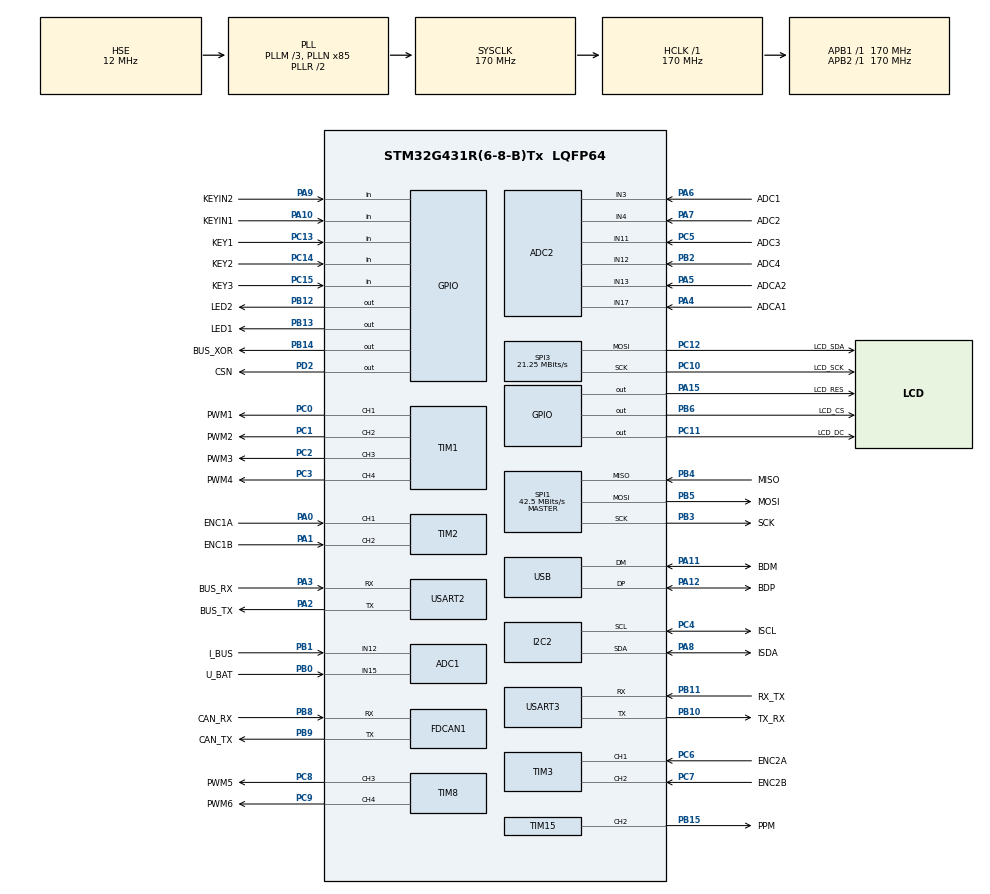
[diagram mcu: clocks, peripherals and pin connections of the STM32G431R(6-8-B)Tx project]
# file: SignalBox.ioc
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ADC1.Channel-0\#ChannelRegularConversion=ADC_CHANNEL_TEMPSENSOR_ADC1
ADC1.NbrOfConversionFlag=1
ADC1.OffsetNumber-0\#ChannelRegularConversion=ADC_OFFSET_NONE
ADC1.Rank-0\#ChannelRegularConversion=1
ADC1.SamplingTime-0\#ChannelRegularConversion=ADC_SAMPLETIME_2CYCLES_5
ADC1.master=1
ADC2.Channel-1\#ChannelRegularConversion=ADC_CHANNEL_3
ADC2.NbrOfConversionFlag=1
ADC2.OffsetNumber-1\#ChannelRegularConversion=ADC_OFFSET_NONE
ADC2.Rank-1\#ChannelRegularConversion=1
ADC2.SamplingTime-1\#ChannelRegularConversion=ADC_SAMPLETIME_2CYCLES_5
FDCAN1.CalculateBaudRateNominal=2125000
FDCAN1.CalculateTimeBitNominal=470
FDCAN1.CalculateTimeQuantumNominal=94.11764705882354
I2C2.Timing=0x30A0A7FB
Mcu.Family=STM32G4
Mcu.Name=STM32G431R(6-8-B)Tx
Mcu.Package=LQFP64
NVIC.PriorityGroup=NVIC_PRIORITYGROUP_4
NVIC.USB_LP_IRQn=true\:0\:0\:false\:false\:true\:false\:true\:true
PA0.GPIO_Label=ENC1A
PA0.Signal=S_TIM2_CH1
PA1.GPIO_Label=ENC1B
PA1.Signal=S_TIM2_CH2
PA10.GPIO_Label=KEYIN1
PA10.Signal=GPIO_Input
PA11.GPIO_Label=BDM
PA11.Mode=Device
PA11.Signal=USB_DM
PA12.GPIO_Label=BDP
PA12.Mode=Device
PA12.Signal=USB_DP
PA13.GPIO_Label=SWDIO
PA13.Mode=Serial_Wire
PA13.Signal=SYS_JTMS-SWDIO
PA14.GPIO_Label=SWCLK
PA14.Mode=Serial_Wire
PA14.Signal=SYS_JTCK-SWCLK
PA15.GPIO_Label=LCD_RES
PA15.Signal=GPIO_Output
PA2.GPIO_Label=BUS_TX
PA2.Mode=Asynchronous
PA2.Signal=USART2_TX
PA3.GPIO_Label=BUS_RX
PA3.Mode=Asynchronous
PA3.Signal=USART2_RX
PA4.GPIO_Label=ADCA1
PA4.Mode=IN17-Single-Ended
PA4.Signal=ADC2_IN17
PA5.GPIO_Label=ADCA2
PA5.Mode=IN13-Single-Ended
PA5.Signal=ADC2_IN13
PA6.GPIO_Label=ADC1
PA6.Mode=IN3-Single-Ended
PA6.Signal=ADC2_IN3
PA7.GPIO_Label=ADC2
PA7.Mode=IN4-Single-Ended
PA7.Signal=ADC2_IN4
PA8.GPIO_Label=ISDA
PA8.Mode=I2C
PA8.Signal=I2C2_SDA
PA9.GPIO_Label=KEYIN2
PA9.Signal=GPIO_Input
PB0.GPIO_Label=U_BAT
PB0.Mode=IN15-Single-Ended
PB0.Signal=ADC1_IN15
PB1.GPIO_Label=I_BUS
PB1.Mode=IN12-Single-Ended
PB1.Signal=ADC1_IN12
PB10.GPIO_Label=TX_RX
PB10.Mode=Asynchronous
PB10.Signal=USART3_TX
PB11.GPIO_Label=RX_TX
PB11.Mode=Asynchronous
PB11.Signal=USART3_RX
PB12.GPIO_Label=LED2
PB12.Signal=GPIO_Output
PB13.GPIO_Label=LED1
PB13.Signal=GPIO_Output
PB14.GPIO_Label=BUS_XOR
PB14.Signal=GPIO_Output
PB15.GPIO_Label=PPM
PB15.Signal=S_TIM15_CH2
PB2.GPIO_Label=ADC4
PB2.Mode=IN12-Single-Ended
PB2.Signal=ADC2_IN12
PB3.GPIO_Label=SCK
PB3.Mode=Full_Duplex_Master
PB3.Signal=SPI1_SCK
PB4.GPIO_Label=MISO
PB4.Mode=Full_Duplex_Master
PB4.Signal=SPI1_MISO
PB5.GPIO_Label=MOSI
PB5.Mode=Full_Duplex_Master
PB5.Signal=SPI1_MOSI
PB6.GPIO_Label=LCD_CS
PB6.Signal=GPIO_Output
PB8-BOOT0.GPIO_Label=CAN_RX
PB8-BOOT0.Mode=FDCAN_Activate
PB8-BOOT0.Signal=FDCAN1_RX
PB9.GPIO_Label=CAN_TX
PB9.Mode=FDCAN_Activate
PB9.Signal=FDCAN1_TX
PC0.GPIO_Label=PWM1
PC0.Signal=S_TIM1_CH1
PC1.GPIO_Label=PWM2
PC1.Signal=S_TIM1_CH2
PC10.GPIO_Label=LCD_SCK
PC10.Mode=TX_Only_Simplex_Unidirect_Master
PC10.Signal=SPI3_SCK
PC11.GPIO_Label=LCD_DC
PC11.Signal=GPIO_Output
PC12.GPIO_Label=LCD_SDA
PC12.Mode=TX_Only_Simplex_Unidirect_Master
PC12.Signal=SPI3_MOSI
PC13.GPIO_Label=KEY1
PC13.Signal=GPIO_Input
PC14-OSC32_IN.GPIO_Label=KEY2
PC14-OSC32_IN.Signal=GPIO_Input
PC15-OSC32_OUT.GPIO_Label=KEY3
PC15-OSC32_OUT.Signal=GPIO_Input
PC2.GPIO_Label=PWM3
PC2.Signal=S_TIM1_CH3
PC3.GPIO_Label=PWM4
PC3.Signal=S_TIM1_CH4
PC4.GPIO_Label=ISCL
PC4.Mode=I2C
PC4.Signal=I2C2_SCL
PC5.GPIO_Label=ADC3
PC5.Mode=IN11-Single-Ended
PC5.Signal=ADC2_IN11
PC6.GPIO_Label=ENC2A
PC6.Signal=S_TIM3_CH1
PC7.GPIO_Label=ENC2B
PC7.Signal=S_TIM3_CH2
PC8.GPIO_Label=PWM5
PC8.Signal=S_TIM8_CH3
PC9.GPIO_Label=PWM6
PC9.Signal=S_TIM8_CH4
PD2.GPIO_Label=CSN
PD2.Signal=GPIO_Output
PF0-OSC_IN.GPIO_Label=O_IN
PF0-OSC_IN.Mode=HSE-External-Oscillator
PF0-OSC_IN.Signal=RCC_OSC_IN
PF1-OSC_OUT.GPIO_Label=O_OUT
PF1-OSC_OUT.Mode=HSE-External-Oscillator
PF1-OSC_OUT.Signal=RCC_OSC_OUT
ProjectManager.HeapSize=0x200
ProjectManager.StackSize=0x400
ProjectManager.TargetToolchain=STM32CubeIDE
RCC.ADC12Freq_Value=170000000
RCC.AHBFreq_Value=170000000
RCC.APB1Freq_Value=170000000
RCC.APB1TimFreq_Value=170000000
RCC.APB2Freq_Value=170000000
RCC.APB2TimFreq_Value=170000000
RCC.CK48CLockSelection=RCC_USBCLKSOURCE_HSI48
RCC.CortexFreq_Value=170000000
RCC.EXTERNAL_CLOCK_VALUE=12288000
RCC.HCLKFreq_Value=170000000
RCC.HSE_VALUE=12000000
RCC.HSI48_VALUE=48000000
RCC.HSI_VALUE=16000000
RCC.LSE_VALUE=32768
RCC.PLLM=RCC_PLLM_DIV3
RCC.PLLN=85
RCC.PLLSourceVirtual=RCC_PLLSOURCE_HSE
RCC.SYSCLKFreq_VALUE=170000000
RCC.SYSCLKSource=RCC_SYSCLKSOURCE_PLLCLK
RCC.USBFreq_Value=48000000
RCC.VCOOutputFreq_Value=340000000
SH.S_TIM15_CH2.0=TIM15_CH2,PWM Generation2 CH2
SH.S_TIM1_CH1.0=TIM1_CH1,PWM Generation1 CH1
SH.S_TIM1_CH2.0=TIM1_CH2,PWM Generation2 CH2
SH.S_TIM1_CH3.0=TIM1_CH3,PWM Generation3 CH3
SH.S_TIM1_CH4.0=TIM1_CH4,PWM Generation4 CH4
SH.S_TIM2_CH1.0=TIM2_CH1,Encoder_Interface
SH.S_TIM2_CH2.0=TIM2_CH2,Encoder_Interface
SH.S_TIM3_CH1.0=TIM3_CH1,Encoder_Interface
SH.S_TIM3_CH2.0=TIM3_CH2,Encoder_Interface
SH.S_TIM8_CH3.0=TIM8_CH3,PWM Generation3 CH3
SH.S_TIM8_CH4.0=TIM8_CH4,PWM Generation4 CH4
SPI1.BaudRatePrescaler=SPI_BAUDRATEPRESCALER_4
SPI1.CalculateBaudRate=42.5 MBits/s
SPI1.Direction=SPI_DIRECTION_2LINES
SPI1.Mode=SPI_MODE_MASTER
SPI1.VirtualType=VM_MASTER
SPI3.BaudRatePrescaler=SPI_BAUDRATEPRESCALER_8
SPI3.CalculateBaudRate=21.25 MBits/s
SPI3.Direction=SPI_DIRECTION_2LINES
SPI3.Mode=SPI_MODE_MASTER
SPI3.VirtualType=VM_MASTER
TIM1.Channel-PWM\ Generation1\ CH1=TIM_CHANNEL_1
TIM1.Channel-PWM\ Generation2\ CH2=TIM_CHANNEL_2
TIM1.Channel-PWM\ Generation3\ CH3=TIM_CHANNEL_3
TIM1.Channel-PWM\ Generation4\ CH4=TIM_CHANNEL_4
TIM15.Channel-PWM\ Generation2\ CH2=TIM_CHANNEL_2
TIM17.Channel=TIM_CHANNEL_1
TIM8.Channel-PWM\ Generation3\ CH3=TIM_CHANNEL_3
TIM8.Channel-PWM\ Generation4\ CH4=TIM_CHANNEL_4
USART2.VirtualMode-Asynchronous=VM_ASYNC
USART3.VirtualMode-Asynchronous=VM_ASYNC
USB_DEVICE.CLASS_NAME_FS=CDC
USB_DEVICE.VirtualMode=Cdc
USB_DEVICE.VirtualModeFS=Cdc_FS
VP_ADC1_TempSens_Input.Mode=IN-TempSens
VP_SYS_VS_DBSignals.Mode=DisableDeadBatterySignals
VP_TIM17_VS_ClockSourceINT.Mode=Enable_Timer
VP_TIM17_VS_no_output1.Mode=Output Compare1 No Output
VP_USB_DEVICE_VS_USB_DEVICE_CDC_FS.Mode=CDC_FS
board=custom

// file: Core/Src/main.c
/* USER CODE BEGIN Header */
/**
  ******************************************************************************
  * @file           : main.c
  * @brief          : Main program body
  ******************************************************************************
  * @attention
  *
  * Copyright (c) 2024 STMicroelectronics.
  * All rights reserved.
  *
  * This software is licensed under terms that can be found in the LICENSE file
  * in the root directory of this software component.
  * If no LICENSE file comes with this software, it is provided AS-IS.
  *
  ******************************************************************************
  */
/* USER CODE END Header */
#include "main.h"
#include "usb_device.h"

ADC_HandleTypeDef hadc1;
ADC_HandleTypeDef hadc2;

FDCAN_HandleTypeDef hfdcan1;

I2C_HandleTypeDef hi2c2;

SPI_HandleTypeDef hspi1;
SPI_HandleTypeDef hspi3;

TIM_HandleTypeDef htim1;
TIM_HandleTypeDef htim2;
TIM_HandleTypeDef htim3;
TIM_HandleTypeDef htim8;
TIM_HandleTypeDef htim15;
TIM_HandleTypeDef htim17;

UART_HandleTypeDef huart2;
UART_HandleTypeDef huart3;

void SystemClock_Config(void);
static void MX_GPIO_Init(void);
static void MX_FDCAN1_Init(void);
static void MX_SPI1_Init(void);
static void MX_SPI3_Init(void);
static void MX_USART3_UART_Init(void);
static void MX_ADC1_Init(void);
static void MX_ADC2_Init(void);
static void MX_I2C2_Init(void);
static void MX_TIM1_Init(void);
static void MX_TIM2_Init(void);
static void MX_TIM3_Init(void);
static void MX_TIM8_Init(void);
static void MX_TIM15_Init(void);
static void MX_TIM17_Init(void);
static void MX_USART2_UART_Init(void);

int main(void)
{

  /* MCU Configuration--------------------------------------------------------*/

  /* Reset of all peripherals, Initializes the Flash interface and the Systick. */
  HAL_Init();

  /* Configure the system clock */
  SystemClock_Config();

  /* Initialize all configured peripherals */
  MX_GPIO_Init();
  MX_FDCAN1_Init();
  MX_SPI1_Init();
  MX_SPI3_Init();
  MX_USART3_UART_Init();
  MX_USB_Device_Init();
  MX_ADC1_Init();
  MX_ADC2_Init();
  MX_I2C2_Init();
  MX_TIM1_Init();
  MX_TIM2_Init();
  MX_TIM3_Init();
  MX_TIM8_Init();
  MX_TIM15_Init();
  MX_TIM17_Init();
  MX_USART2_UART_Init();

  /* Infinite loop */
  while (1)
  {

    /* USER CODE BEGIN 3 */
	HAL_GPIO_WritePin(LED1_GPIO_Port, LED1_Pin, !HAL_GPIO_ReadPin(KEY1_GPIO_Port, KEY1_Pin));
	HAL_GPIO_WritePin(LED2_GPIO_Port, LED2_Pin, !HAL_GPIO_ReadPin(KEY2_GPIO_Port, KEY2_Pin));
  }
  /* USER CODE END 3 */
}

void SystemClock_Config(void)
{
  RCC_OscInitTypeDef RCC_OscInitStruct = {0};
  RCC_ClkInitTypeDef RCC_ClkInitStruct = {0};

  /** Configure the main internal regulator output voltage
  */
  HAL_PWREx_ControlVoltageScaling(PWR_REGULATOR_VOLTAGE_SCALE1_BOOST);

  /** Initializes the RCC Oscillators according to the specified parameters
  * in the RCC_OscInitTypeDef structure.
  */
  RCC_OscInitStruct.OscillatorType = RCC_OSCILLATORTYPE_HSI48|RCC_OSCILLATORTYPE_HSE;
  RCC_OscInitStruct.HSEState = RCC_HSE_ON;
  RCC_OscInitStruct.HSI48State = RCC_HSI48_ON;
  RCC_OscInitStruct.PLL.PLLState = RCC_PLL_ON;
  RCC_OscInitStruct.PLL.PLLSource = RCC_PLLSOURCE_HSE;
  RCC_OscInitStruct.PLL.PLLM = RCC_PLLM_DIV3;
  RCC_OscInitStruct.PLL.PLLN = 85;
  RCC_OscInitStruct.PLL.PLLP = RCC_PLLP_DIV2;
  RCC_OscInitStruct.PLL.PLLQ = RCC_PLLQ_DIV2;
  RCC_OscInitStruct.PLL.PLLR = RCC_PLLR_DIV2;
  if (HAL_RCC_OscConfig(&RCC_OscInitStruct) != HAL_OK)
  {
    Error_Handler();
  }

  /** Initializes the CPU, AHB and APB buses clocks
  */
  RCC_ClkInitStruct.ClockType = RCC_CLOCKTYPE_HCLK|RCC_CLOCKTYPE_SYSCLK
                              |RCC_CLOCKTYPE_PCLK1|RCC_CLOCKTYPE_PCLK2;
  RCC_ClkInitStruct.SYSCLKSource = RCC_SYSCLKSOURCE_PLLCLK;
  RCC_ClkInitStruct.AHBCLKDivider = RCC_SYSCLK_DIV1;
  RCC_ClkInitStruct.APB1CLKDivider = RCC_HCLK_DIV1;
  RCC_ClkInitStruct.APB2CLKDivider = RCC_HCLK_DIV1;

  if (HAL_RCC_ClockConfig(&RCC_ClkInitStruct, FLASH_LATENCY_4) != HAL_OK)
  {
    Error_Handler();
  }
}

static void MX_ADC1_Init(void)
{

  ADC_MultiModeTypeDef multimode = {0};
  ADC_ChannelConfTypeDef sConfig = {0};

  /** Common config
  */
  hadc1.Instance = ADC1;
  hadc1.Init.ClockPrescaler = ADC_CLOCK_SYNC_PCLK_DIV4;
  hadc1.Init.Resolution = ADC_RESOLUTION_12B;
  hadc1.Init.DataAlign = ADC_DATAALIGN_RIGHT;
  hadc1.Init.GainCompensation = 0;
  hadc1.Init.ScanConvMode = ADC_SCAN_DISABLE;
  hadc1.Init.EOCSelection = ADC_EOC_SINGLE_CONV;
  hadc1.Init.LowPowerAutoWait = DISABLE;
  hadc1.Init.ContinuousConvMode = DISABLE;
  hadc1.Init.NbrOfConversion = 1;
  hadc1.Init.DiscontinuousConvMode = DISABLE;
  hadc1.Init.ExternalTrigConv = ADC_SOFTWARE_START;
  hadc1.Init.ExternalTrigConvEdge = ADC_EXTERNALTRIGCONVEDGE_NONE;
  hadc1.Init.DMAContinuousRequests = DISABLE;
  hadc1.Init.Overrun = ADC_OVR_DATA_PRESERVED;
  hadc1.Init.OversamplingMode = DISABLE;
  if (HAL_ADC_Init(&hadc1) != HAL_OK)
  {
    Error_Handler();
  }

  /** Configure the ADC multi-mode
  */
  multimode.Mode = ADC_MODE_INDEPENDENT;
  if (HAL_ADCEx_MultiModeConfigChannel(&hadc1, &multimode) != HAL_OK)
  {
    Error_Handler();
  }

  /** Configure Regular Channel
  */
  sConfig.Channel = ADC_CHANNEL_TEMPSENSOR_ADC1;
  sConfig.Rank = ADC_REGULAR_RANK_1;
  sConfig.SamplingTime = ADC_SAMPLETIME_2CYCLES_5;
  sConfig.SingleDiff = ADC_SINGLE_ENDED;
  sConfig.OffsetNumber = ADC_OFFSET_NONE;
  sConfig.Offset = 0;
  if (HAL_ADC_ConfigChannel(&hadc1, &sConfig) != HAL_OK)
  {
    Error_Handler();
  }

}

static void MX_ADC2_Init(void)
{

  ADC_ChannelConfTypeDef sConfig = {0};

  /** Common config
  */
  hadc2.Instance = ADC2;
  hadc2.Init.ClockPrescaler = ADC_CLOCK_SYNC_PCLK_DIV4;
  hadc2.Init.Resolution = ADC_RESOLUTION_12B;
  hadc2.Init.DataAlign = ADC_DATAALIGN_RIGHT;
  hadc2.Init.GainCompensation = 0;
  hadc2.Init.ScanConvMode = ADC_SCAN_DISABLE;
  hadc2.Init.EOCSelection = ADC_EOC_SINGLE_CONV;
  hadc2.Init.LowPowerAutoWait = DISABLE;
  hadc2.Init.ContinuousConvMode = DISABLE;
  hadc2.Init.NbrOfConversion = 1;
  hadc2.Init.DiscontinuousConvMode = DISABLE;
  hadc2.Init.ExternalTrigConv = ADC_SOFTWARE_START;
  hadc2.Init.ExternalTrigConvEdge = ADC_EXTERNALTRIGCONVEDGE_NONE;
  hadc2.Init.DMAContinuousRequests = DISABLE;
  hadc2.Init.Overrun = ADC_OVR_DATA_PRESERVED;
  hadc2.Init.OversamplingMode = DISABLE;
  if (HAL_ADC_Init(&hadc2) != HAL_OK)
  {
    Error_Handler();
  }

  /** Configure Regular Channel
  */
  sConfig.Channel = ADC_CHANNEL_3;
  sConfig.Rank = ADC_REGULAR_RANK_1;
  sConfig.SamplingTime = ADC_SAMPLETIME_2CYCLES_5;
  sConfig.SingleDiff = ADC_SINGLE_ENDED;
  sConfig.OffsetNumber = ADC_OFFSET_NONE;
  sConfig.Offset = 0;
  if (HAL_ADC_ConfigChannel(&hadc2, &sConfig) != HAL_OK)
  {
    Error_Handler();
  }

}

static void MX_FDCAN1_Init(void)
{

  hfdcan1.Instance = FDCAN1;
  hfdcan1.Init.ClockDivider = FDCAN_CLOCK_DIV1;
  hfdcan1.Init.FrameFormat = FDCAN_FRAME_CLASSIC;
  hfdcan1.Init.Mode = FDCAN_MODE_NORMAL;
  hfdcan1.Init.AutoRetransmission = DISABLE;
  hfdcan1.Init.TransmitPause = DISABLE;
  hfdcan1.Init.ProtocolException = DISABLE;
  hfdcan1.Init.NominalPrescaler = 16;
  hfdcan1.Init.NominalSyncJumpWidth = 1;
  hfdcan1.Init.NominalTimeSeg1 = 2;
  hfdcan1.Init.NominalTimeSeg2 = 2;
  hfdcan1.Init.DataPrescaler = 1;
  hfdcan1.Init.DataSyncJumpWidth = 1;
  hfdcan1.Init.DataTimeSeg1 = 1;
  hfdcan1.Init.DataTimeSeg2 = 1;
  hfdcan1.Init.StdFiltersNbr = 0;
  hfdcan1.Init.ExtFiltersNbr = 0;
  hfdcan1.Init.TxFifoQueueMode = FDCAN_TX_FIFO_OPERATION;
  if (HAL_FDCAN_Init(&hfdcan1) != HAL_OK)
  {
    Error_Handler();
  }

}

static void MX_I2C2_Init(void)
{

  hi2c2.Instance = I2C2;
  hi2c2.Init.Timing = 0x30A0A7FB;
  hi2c2.Init.OwnAddress1 = 0;
  hi2c2.Init.AddressingMode = I2C_ADDRESSINGMODE_7BIT;
  hi2c2.Init.DualAddressMode = I2C_DUALADDRESS_DISABLE;
  hi2c2.Init.OwnAddress2 = 0;
  hi2c2.Init.OwnAddress2Masks = I2C_OA2_NOMASK;
  hi2c2.Init.GeneralCallMode = I2C_GENERALCALL_DISABLE;
  hi2c2.Init.NoStretchMode = I2C_NOSTRETCH_DISABLE;
  if (HAL_I2C_Init(&hi2c2) != HAL_OK)
  {
    Error_Handler();
  }

  /** Configure Analogue filter
  */
  if (HAL_I2CEx_ConfigAnalogFilter(&hi2c2, I2C_ANALOGFILTER_ENABLE) != HAL_OK)
  {
    Error_Handler();
  }

  /** Configure Digital filter
  */
  if (HAL_I2CEx_ConfigDigitalFilter(&hi2c2, 0) != HAL_OK)
  {
    Error_Handler();
  }

}

static void MX_SPI1_Init(void)
{

  /* SPI1 parameter configuration*/
  hspi1.Instance = SPI1;
  hspi1.Init.Mode = SPI_MODE_MASTER;
  hspi1.Init.Direction = SPI_DIRECTION_2LINES;
  hspi1.Init.DataSize = SPI_DATASIZE_4BIT;
  hspi1.Init.CLKPolarity = SPI_POLARITY_LOW;
  hspi1.Init.CLKPhase = SPI_PHASE_1EDGE;
  hspi1.Init.NSS = SPI_NSS_SOFT;
  hspi1.Init.BaudRatePrescaler = SPI_BAUDRATEPRESCALER_4;
  hspi1.Init.FirstBit = SPI_FIRSTBIT_MSB;
  hspi1.Init.TIMode = SPI_TIMODE_DISABLE;
  hspi1.Init.CRCCalculation = SPI_CRCCALCULATION_DISABLE;
  hspi1.Init.CRCPolynomial = 7;
  hspi1.Init.CRCLength = SPI_CRC_LENGTH_DATASIZE;
  hspi1.Init.NSSPMode = SPI_NSS_PULSE_ENABLE;
  if (HAL_SPI_Init(&hspi1) != HAL_OK)
  {
    Error_Handler();
  }

}

static void MX_SPI3_Init(void)
{

  /* SPI3 parameter configuration*/
  hspi3.Instance = SPI3;
  hspi3.Init.Mode = SPI_MODE_MASTER;
  hspi3.Init.Direction = SPI_DIRECTION_2LINES;
  hspi3.Init.DataSize = SPI_DATASIZE_4BIT;
  hspi3.Init.CLKPolarity = SPI_POLARITY_LOW;
  hspi3.Init.CLKPhase = SPI_PHASE_1EDGE;
  hspi3.Init.NSS = SPI_NSS_SOFT;
  hspi3.Init.BaudRatePrescaler = SPI_BAUDRATEPRESCALER_8;
  hspi3.Init.FirstBit = SPI_FIRSTBIT_MSB;
  hspi3.Init.TIMode = SPI_TIMODE_DISABLE;
  hspi3.Init.CRCCalculation = SPI_CRCCALCULATION_DISABLE;
  hspi3.Init.CRCPolynomial = 7;
  hspi3.Init.CRCLength = SPI_CRC_LENGTH_DATASIZE;
  hspi3.Init.NSSPMode = SPI_NSS_PULSE_ENABLE;
  if (HAL_SPI_Init(&hspi3) != HAL_OK)
  {
    Error_Handler();
  }

}

static void MX_TIM1_Init(void)
{

  TIM_MasterConfigTypeDef sMasterConfig = {0};
  TIM_OC_InitTypeDef sConfigOC = {0};
  TIM_BreakDeadTimeConfigTypeDef sBreakDeadTimeConfig = {0};

  htim1.Instance = TIM1;
  htim1.Init.Prescaler = 0;
  htim1.Init.CounterMode = TIM_COUNTERMODE_UP;
  htim1.Init.Period = 65535;
  htim1.Init.ClockDivision = TIM_CLOCKDIVISION_DIV1;
  htim1.Init.RepetitionCounter = 0;
  htim1.Init.AutoReloadPreload = TIM_AUTORELOAD_PRELOAD_DISABLE;
  if (HAL_TIM_PWM_Init(&htim1) != HAL_OK)
  {
    Error_Handler();
  }
  sMasterConfig.MasterOutputTrigger = TIM_TRGO_RESET;
  sMasterConfig.MasterOutputTrigger2 = TIM_TRGO2_RESET;
  sMasterConfig.MasterSlaveMode = TIM_MASTERSLAVEMODE_DISABLE;
  if (HAL_TIMEx_MasterConfigSynchronization(&htim1, &sMasterConfig) != HAL_OK)
  {
    Error_Handler();
  }
  sConfigOC.OCMode = TIM_OCMODE_PWM1;
  sConfigOC.Pulse = 0;
  sConfigOC.OCPolarity = TIM_OCPOLARITY_HIGH;
  sConfigOC.OCNPolarity = TIM_OCNPOLARITY_HIGH;
  sConfigOC.OCFastMode = TIM_OCFAST_DISABLE;
  sConfigOC.OCIdleState = TIM_OCIDLESTATE_RESET;
  sConfigOC.OCNIdleState = TIM_OCNIDLESTATE_RESET;
  if (HAL_TIM_PWM_ConfigChannel(&htim1, &sConfigOC, TIM_CHANNEL_1) != HAL_OK)
  {
    Error_Handler();
  }
  if (HAL_TIM_PWM_ConfigChannel(&htim1, &sConfigOC, TIM_CHANNEL_2) != HAL_OK)
  {
    Error_Handler();
  }
  if (HAL_TIM_PWM_ConfigChannel(&htim1, &sConfigOC, TIM_CHANNEL_3) != HAL_OK)
  {
    Error_Handler();
  }
  if (HAL_TIM_PWM_ConfigChannel(&htim1, &sConfigOC, TIM_CHANNEL_4) != HAL_OK)
  {
    Error_Handler();
  }
  sBreakDeadTimeConfig.OffStateRunMode = TIM_OSSR_DISABLE;
  sBreakDeadTimeConfig.OffStateIDLEMode = TIM_OSSI_DISABLE;
  sBreakDeadTimeConfig.LockLevel = TIM_LOCKLEVEL_OFF;
  sBreakDeadTimeConfig.DeadTime = 0;
  sBreakDeadTimeConfig.BreakState = TIM_BREAK_DISABLE;
  sBreakDeadTimeConfig.BreakPolarity = TIM_BREAKPOLARITY_HIGH;
  sBreakDeadTimeConfig.BreakFilter = 0;
  sBreakDeadTimeConfig.BreakAFMode = TIM_BREAK_AFMODE_INPUT;
  sBreakDeadTimeConfig.Break2State = TIM_BREAK2_DISABLE;
  sBreakDeadTimeConfig.Break2Polarity = TIM_BREAK2POLARITY_HIGH;
  sBreakDeadTimeConfig.Break2Filter = 0;
  sBreakDeadTimeConfig.Break2AFMode = TIM_BREAK_AFMODE_INPUT;
  sBreakDeadTimeConfig.AutomaticOutput = TIM_AUTOMATICOUTPUT_DISABLE;
  if (HAL_TIMEx_ConfigBreakDeadTime(&htim1, &sBreakDeadTimeConfig) != HAL_OK)
  {
    Error_Handler();
  }
  HAL_TIM_MspPostInit(&htim1);

}

static void MX_TIM2_Init(void)
{

  TIM_Encoder_InitTypeDef sConfig = {0};
  TIM_MasterConfigTypeDef sMasterConfig = {0};

  htim2.Instance = TIM2;
  htim2.Init.Prescaler = 0;
  htim2.Init.CounterMode = TIM_COUNTERMODE_UP;
  htim2.Init.Period = 4294967295;
  htim2.Init.ClockDivision = TIM_CLOCKDIVISION_DIV1;
  htim2.Init.AutoReloadPreload = TIM_AUTORELOAD_PRELOAD_DISABLE;
  sConfig.EncoderMode = TIM_ENCODERMODE_TI1;
  sConfig.IC1Polarity = TIM_ICPOLARITY_RISING;
  sConfig.IC1Selection = TIM_ICSELECTION_DIRECTTI;
  sConfig.IC1Prescaler = TIM_ICPSC_DIV1;
  sConfig.IC1Filter = 0;
  sConfig.IC2Polarity = TIM_ICPOLARITY_RISING;
  sConfig.IC2Selection = TIM_ICSELECTION_DIRECTTI;
  sConfig.IC2Prescaler = TIM_ICPSC_DIV1;
  sConfig.IC2Filter = 0;
  if (HAL_TIM_Encoder_Init(&htim2, &sConfig) != HAL_OK)
  {
    Error_Handler();
  }
  sMasterConfig.MasterOutputTrigger = TIM_TRGO_RESET;
  sMasterConfig.MasterSlaveMode = TIM_MASTERSLAVEMODE_DISABLE;
  if (HAL_TIMEx_MasterConfigSynchronization(&htim2, &sMasterConfig) != HAL_OK)
  {
    Error_Handler();
  }

}

static void MX_TIM3_Init(void)
{

  TIM_Encoder_InitTypeDef sConfig = {0};
  TIM_MasterConfigTypeDef sMasterConfig = {0};

  htim3.Instance = TIM3;
  htim3.Init.Prescaler = 0;
  htim3.Init.CounterMode = TIM_COUNTERMODE_UP;
  htim3.Init.Period = 65535;
  htim3.Init.ClockDivision = TIM_CLOCKDIVISION_DIV1;
  htim3.Init.AutoReloadPreload = TIM_AUTORELOAD_PRELOAD_DISABLE;
  sConfig.EncoderMode = TIM_ENCODERMODE_TI1;
  sConfig.IC1Polarity = TIM_ICPOLARITY_RISING;
  sConfig.IC1Selection = TIM_ICSELECTION_DIRECTTI;
  sConfig.IC1Prescaler = TIM_ICPSC_DIV1;
  sConfig.IC1Filter = 0;
  sConfig.IC2Polarity = TIM_ICPOLARITY_RISING;
  sConfig.IC2Selection = TIM_ICSELECTION_DIRECTTI;
  sConfig.IC2Prescaler = TIM_ICPSC_DIV1;
  sConfig.IC2Filter = 0;
  if (HAL_TIM_Encoder_Init(&htim3, &sConfig) != HAL_OK)
  {
    Error_Handler();
  }
  sMasterConfig.MasterOutputTrigger = TIM_TRGO_RESET;
  sMasterConfig.MasterSlaveMode = TIM_MASTERSLAVEMODE_DISABLE;
  if (HAL_TIMEx_MasterConfigSynchronization(&htim3, &sMasterConfig) != HAL_OK)
  {
    Error_Handler();
  }

}

static void MX_TIM8_Init(void)
{

  TIM_MasterConfigTypeDef sMasterConfig = {0};
  TIM_OC_InitTypeDef sConfigOC = {0};
  TIM_BreakDeadTimeConfigTypeDef sBreakDeadTimeConfig = {0};

  htim8.Instance = TIM8;
  htim8.Init.Prescaler = 0;
  htim8.Init.CounterMode = TIM_COUNTERMODE_UP;
  htim8.Init.Period = 65535;
  htim8.Init.ClockDivision = TIM_CLOCKDIVISION_DIV1;
  htim8.Init.RepetitionCounter = 0;
  htim8.Init.AutoReloadPreload = TIM_AUTORELOAD_PRELOAD_DISABLE;
  if (HAL_TIM_PWM_Init(&htim8) != HAL_OK)
  {
    Error_Handler();
  }
  sMasterConfig.MasterOutputTrigger = TIM_TRGO_RESET;
  sMasterConfig.MasterOutputTrigger2 = TIM_TRGO2_RESET;
  sMasterConfig.MasterSlaveMode = TIM_MASTERSLAVEMODE_DISABLE;
  if (HAL_TIMEx_MasterConfigSynchronization(&htim8, &sMasterConfig) != HAL_OK)
  {
    Error_Handler();
  }
  sConfigOC.OCMode = TIM_OCMODE_PWM1;
  sConfigOC.Pulse = 0;
  sConfigOC.OCPolarity = TIM_OCPOLARITY_HIGH;
  sConfigOC.OCNPolarity = TIM_OCNPOLARITY_HIGH;
  sConfigOC.OCFastMode = TIM_OCFAST_DISABLE;
  sConfigOC.OCIdleState = TIM_OCIDLESTATE_RESET;
  sConfigOC.OCNIdleState = TIM_OCNIDLESTATE_RESET;
  if (HAL_TIM_PWM_ConfigChannel(&htim8, &sConfigOC, TIM_CHANNEL_3) != HAL_OK)
  {
    Error_Handler();
  }
  if (HAL_TIM_PWM_ConfigChannel(&htim8, &sConfigOC, TIM_CHANNEL_4) != HAL_OK)
  {
    Error_Handler();
  }
  sBreakDeadTimeConfig.OffStateRunMode = TIM_OSSR_DISABLE;
  sBreakDeadTimeConfig.OffStateIDLEMode = TIM_OSSI_DISABLE;
  sBreakDeadTimeConfig.LockLevel = TIM_LOCKLEVEL_OFF;
  sBreakDeadTimeConfig.DeadTime = 0;
  sBreakDeadTimeConfig.BreakState = TIM_BREAK_DISABLE;
  sBreakDeadTimeConfig.BreakPolarity = TIM_BREAKPOLARITY_HIGH;
  sBreakDeadTimeConfig.BreakFilter = 0;
  sBreakDeadTimeConfig.BreakAFMode = TIM_BREAK_AFMODE_INPUT;
  sBreakDeadTimeConfig.Break2State = TIM_BREAK2_DISABLE;
  sBreakDeadTimeConfig.Break2Polarity = TIM_BREAK2POLARITY_HIGH;
  sBreakDeadTimeConfig.Break2Filter = 0;
  sBreakDeadTimeConfig.Break2AFMode = TIM_BREAK_AFMODE_INPUT;
  sBreakDeadTimeConfig.AutomaticOutput = TIM_AUTOMATICOUTPUT_DISABLE;
  if (HAL_TIMEx_ConfigBreakDeadTime(&htim8, &sBreakDeadTimeConfig) != HAL_OK)
  {
    Error_Handler();
  }
  HAL_TIM_MspPostInit(&htim8);

}

static void MX_TIM15_Init(void)
{

  TIM_MasterConfigTypeDef sMasterConfig = {0};
  TIM_OC_InitTypeDef sConfigOC = {0};
  TIM_BreakDeadTimeConfigTypeDef sBreakDeadTimeConfig = {0};

  htim15.Instance = TIM15;
  htim15.Init.Prescaler = 0;
  htim15.Init.CounterMode = TIM_COUNTERMODE_UP;
  htim15.Init.Period = 65535;
  htim15.Init.ClockDivision = TIM_CLOCKDIVISION_DIV1;
  htim15.Init.RepetitionCounter = 0;
  htim15.Init.AutoReloadPreload = TIM_AUTORELOAD_PRELOAD_DISABLE;
  if (HAL_TIM_PWM_Init(&htim15) != HAL_OK)
  {
    Error_Handler();
  }
  sMasterConfig.MasterOutputTrigger = TIM_TRGO_RESET;
  sMasterConfig.MasterSlaveMode = TIM_MASTERSLAVEMODE_DISABLE;
  if (HAL_TIMEx_MasterConfigSynchronization(&htim15, &sMasterConfig) != HAL_OK)
  {
    Error_Handler();
  }
  sConfigOC.OCMode = TIM_OCMODE_PWM1;
  sConfigOC.Pulse = 0;
  sConfigOC.OCPolarity = TIM_OCPOLARITY_HIGH;
  sConfigOC.OCNPolarity = TIM_OCNPOLARITY_HIGH;
  sConfigOC.OCFastMode = TIM_OCFAST_DISABLE;
  sConfigOC.OCIdleState = TIM_OCIDLESTATE_RESET;
  sConfigOC.OCNIdleState = TIM_OCNIDLESTATE_RESET;
  if (HAL_TIM_PWM_ConfigChannel(&htim15, &sConfigOC, TIM_CHANNEL_2) != HAL_OK)
  {
    Error_Handler();
  }
  sBreakDeadTimeConfig.OffStateRunMode = TIM_OSSR_DISABLE;
  sBreakDeadTimeConfig.OffStateIDLEMode = TIM_OSSI_DISABLE;
  sBreakDeadTimeConfig.LockLevel = TIM_LOCKLEVEL_OFF;
  sBreakDeadTimeConfig.DeadTime = 0;
  sBreakDeadTimeConfig.BreakState = TIM_BREAK_DISABLE;
  sBreakDeadTimeConfig.BreakPolarity = TIM_BREAKPOLARITY_HIGH;
  sBreakDeadTimeConfig.BreakFilter = 0;
  sBreakDeadTimeConfig.AutomaticOutput = TIM_AUTOMATICOUTPUT_DISABLE;
  if (HAL_TIMEx_ConfigBreakDeadTime(&htim15, &sBreakDeadTimeConfig) != HAL_OK)
  {
    Error_Handler();
  }
  HAL_TIM_MspPostInit(&htim15);

}

static void MX_TIM17_Init(void)
{

  TIM_OC_InitTypeDef sConfigOC = {0};
  TIM_BreakDeadTimeConfigTypeDef sBreakDeadTimeConfig = {0};

  htim17.Instance = TIM17;
  htim17.Init.Prescaler = 0;
  htim17.Init.CounterMode = TIM_COUNTERMODE_UP;
  htim17.Init.Period = 65535;
  htim17.Init.ClockDivision = TIM_CLOCKDIVISION_DIV1;
  htim17.Init.RepetitionCounter = 0;
  htim17.Init.AutoReloadPreload = TIM_AUTORELOAD_PRELOAD_DISABLE;
  if (HAL_TIM_Base_Init(&htim17) != HAL_OK)
  {
    Error_Handler();
  }
  if (HAL_TIM_OC_Init(&htim17) != HAL_OK)
  {
    Error_Handler();
  }
  sConfigOC.OCMode = TIM_OCMODE_TIMING;
  sConfigOC.Pulse = 0;
  sConfigOC.OCPolarity = TIM_OCPOLARITY_HIGH;
  sConfigOC.OCNPolarity = TIM_OCNPOLARITY_HIGH;
  sConfigOC.OCFastMode = TIM_OCFAST_DISABLE;
  sConfigOC.OCIdleState = TIM_OCIDLESTATE_RESET;
  sConfigOC.OCNIdleState = TIM_OCNIDLESTATE_RESET;
  if (HAL_TIM_OC_ConfigChannel(&htim17, &sConfigOC, TIM_CHANNEL_1) != HAL_OK)
  {
    Error_Handler();
  }
  sBreakDeadTimeConfig.OffStateRunMode = TIM_OSSR_DISABLE;
  sBreakDeadTimeConfig.OffStateIDLEMode = TIM_OSSI_DISABLE;
  sBreakDeadTimeConfig.LockLevel = TIM_LOCKLEVEL_OFF;
  sBreakDeadTimeConfig.DeadTime = 0;
  sBreakDeadTimeConfig.BreakState = TIM_BREAK_DISABLE;
  sBreakDeadTimeConfig.BreakPolarity = TIM_BREAKPOLARITY_HIGH;
  sBreakDeadTimeConfig.BreakFilter = 0;
  sBreakDeadTimeConfig.AutomaticOutput = TIM_AUTOMATICOUTPUT_DISABLE;
  if (HAL_TIMEx_ConfigBreakDeadTime(&htim17, &sBreakDeadTimeConfig) != HAL_OK)
  {
    Error_Handler();
  }

}

static void MX_USART2_UART_Init(void)
{

  huart2.Instance = USART2;
  huart2.Init.BaudRate = 115200;
  huart2.Init.WordLength = UART_WORDLENGTH_8B;
  huart2.Init.StopBits = UART_STOPBITS_1;
  huart2.Init.Parity = UART_PARITY_NONE;
  huart2.Init.Mode = UART_MODE_TX_RX;
  huart2.Init.HwFlowCtl = UART_HWCONTROL_NONE;
  huart2.Init.OverSampling = UART_OVERSAMPLING_16;
  huart2.Init.OneBitSampling = UART_ONE_BIT_SAMPLE_DISABLE;
  huart2.Init.ClockPrescaler = UART_PRESCALER_DIV1;
  huart2.AdvancedInit.AdvFeatureInit = UART_ADVFEATURE_NO_INIT;
  if (HAL_UART_Init(&huart2) != HAL_OK)
  {
    Error_Handler();
  }
  if (HAL_UARTEx_SetTxFifoThreshold(&huart2, UART_TXFIFO_THRESHOLD_1_8) != HAL_OK)
  {
    Error_Handler();
  }
  if (HAL_UARTEx_SetRxFifoThreshold(&huart2, UART_RXFIFO_THRESHOLD_1_8) != HAL_OK)
  {
    Error_Handler();
  }
  if (HAL_UARTEx_DisableFifoMode(&huart2) != HAL_OK)
  {
    Error_Handler();
  }

}

static void MX_USART3_UART_Init(void)
{

  huart3.Instance = USART3;
  huart3.Init.BaudRate = 115200;
  huart3.Init.WordLength = UART_WORDLENGTH_8B;
  huart3.Init.StopBits = UART_STOPBITS_1;
  huart3.Init.Parity = UART_PARITY_NONE;
  huart3.Init.Mode = UART_MODE_TX_RX;
  huart3.Init.HwFlowCtl = UART_HWCONTROL_NONE;
  huart3.Init.OverSampling = UART_OVERSAMPLING_16;
  huart3.Init.OneBitSampling = UART_ONE_BIT_SAMPLE_DISABLE;
  huart3.Init.ClockPrescaler = UART_PRESCALER_DIV1;
  huart3.AdvancedInit.AdvFeatureInit = UART_ADVFEATURE_NO_INIT;
  if (HAL_UART_Init(&huart3) != HAL_OK)
  {
    Error_Handler();
  }
  if (HAL_UARTEx_SetTxFifoThreshold(&huart3, UART_TXFIFO_THRESHOLD_1_8) != HAL_OK)
  {
    Error_Handler();
  }
  if (HAL_UARTEx_SetRxFifoThreshold(&huart3, UART_RXFIFO_THRESHOLD_1_8) != HAL_OK)
  {
    Error_Handler();
  }
  if (HAL_UARTEx_DisableFifoMode(&huart3) != HAL_OK)
  {
    Error_Handler();
  }

}

static void MX_GPIO_Init(void)
{
  GPIO_InitTypeDef GPIO_InitStruct = {0};

  /* GPIO Ports Clock Enable */
  __HAL_RCC_GPIOC_CLK_ENABLE();
  __HAL_RCC_GPIOF_CLK_ENABLE();
  __HAL_RCC_GPIOA_CLK_ENABLE();
  __HAL_RCC_GPIOB_CLK_ENABLE();
  __HAL_RCC_GPIOD_CLK_ENABLE();

  /*Configure GPIO pin Output Level */
  HAL_GPIO_WritePin(GPIOB, LED2_Pin|LED1_Pin|BUS_XOR_Pin|LCD_CS_Pin, GPIO_PIN_RESET);

  /*Configure GPIO pin Output Level */
  HAL_GPIO_WritePin(LCD_RES_GPIO_Port, LCD_RES_Pin, GPIO_PIN_RESET);

  /*Configure GPIO pin Output Level */
  HAL_GPIO_WritePin(LCD_DC_GPIO_Port, LCD_DC_Pin, GPIO_PIN_RESET);

  /*Configure GPIO pin Output Level */
  HAL_GPIO_WritePin(CSN_GPIO_Port, CSN_Pin, GPIO_PIN_RESET);

  /*Configure GPIO pins : KEY1_Pin KEY2_Pin KEY3_Pin */
  GPIO_InitStruct.Pin = KEY1_Pin|KEY2_Pin|KEY3_Pin;
  GPIO_InitStruct.Mode = GPIO_MODE_INPUT;
  GPIO_InitStruct.Pull = GPIO_NOPULL;
  HAL_GPIO_Init(GPIOC, &GPIO_InitStruct);

  /*Configure GPIO pins : LED2_Pin LED1_Pin BUS_XOR_Pin LCD_CS_Pin */
  GPIO_InitStruct.Pin = LED2_Pin|LED1_Pin|BUS_XOR_Pin|LCD_CS_Pin;
  GPIO_InitStruct.Mode = GPIO_MODE_OUTPUT_PP;
  GPIO_InitStruct.Pull = GPIO_NOPULL;
  GPIO_InitStruct.Speed = GPIO_SPEED_FREQ_LOW;
  HAL_GPIO_Init(GPIOB, &GPIO_InitStruct);

  /*Configure GPIO pins : KEYIN2_Pin KEYIN1_Pin */
  GPIO_InitStruct.Pin = KEYIN2_Pin|KEYIN1_Pin;
  GPIO_InitStruct.Mode = GPIO_MODE_INPUT;
  GPIO_InitStruct.Pull = GPIO_NOPULL;
  HAL_GPIO_Init(GPIOA, &GPIO_InitStruct);

  /*Configure GPIO pin : LCD_RES_Pin */
  GPIO_InitStruct.Pin = LCD_RES_Pin;
  GPIO_InitStruct.Mode = GPIO_MODE_OUTPUT_PP;
  GPIO_InitStruct.Pull = GPIO_NOPULL;
  GPIO_InitStruct.Speed = GPIO_SPEED_FREQ_LOW;
  HAL_GPIO_Init(LCD_RES_GPIO_Port, &GPIO_InitStruct);

  /*Configure GPIO pin : LCD_DC_Pin */
  GPIO_InitStruct.Pin = LCD_DC_Pin;
  GPIO_InitStruct.Mode = GPIO_MODE_OUTPUT_PP;
  GPIO_InitStruct.Pull = GPIO_NOPULL;
  GPIO_InitStruct.Speed = GPIO_SPEED_FREQ_LOW;
  HAL_GPIO_Init(LCD_DC_GPIO_Port, &GPIO_InitStruct);

  /*Configure GPIO pin : CSN_Pin */
  GPIO_InitStruct.Pin = CSN_Pin;
  GPIO_InitStruct.Mode = GPIO_MODE_OUTPUT_PP;
  GPIO_InitStruct.Pull = GPIO_NOPULL;
  GPIO_InitStruct.Speed = GPIO_SPEED_FREQ_LOW;
  HAL_GPIO_Init(CSN_GPIO_Port, &GPIO_InitStruct);

}

void Error_Handler(void)
{
  __disable_irq();
  while (1)
  {
  }
}
